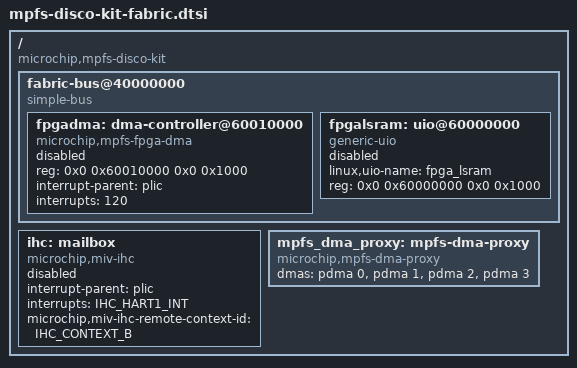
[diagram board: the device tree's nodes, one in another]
// SPDX-License-Identifier: (GPL-2.0 OR MIT)
/* Copyright (c) 2020-2021 Microchip Technology Inc */

#include "dt-bindings/mailbox/miv-ihc.h"

/ {
	compatible = "microchip,mpfs-disco-kit", "microchip,mpfs";

	fabric-bus@40000000 {
		compatible = "simple-bus";
		#address-cells = <2>;
		#size-cells = <2>;
		ranges = <0x0 0x40000000 0x0 0x40000000 0x0 0x20000000>, /* FIC3-FAB */
			 <0x0 0x60000000 0x0 0x60000000 0x0 0x20000000>, /* FIC0, LO */
			 <0x0 0xe0000000 0x0 0xe0000000 0x0 0x20000000>, /* FIC1, LO */
			 <0x20 0x0 0x20 0x0 0x10 0x0>, /* FIC0,HI */
			 <0x30 0x0 0x30 0x0 0x10 0x0>; /* FIC1,HI */

		fpgadma: dma-controller@60010000 {
			compatible = "microchip,mpfs-fpga-dma";
			reg = <0x0 0x60010000 0x0 0x1000>;
			interrupt-parent = <&plic>;
			interrupts = <120>;
			#dma-cells = <1>;
			status = "disabled";
		};

		fpgalsram: uio@60000000 {
			compatible = "generic-uio";
			linux,uio-name = "fpga_lsram";
			reg = <0x0 0x60000000 0x0 0x1000>;
			status = "disabled";
		};
	};

	ihc: mailbox {
		compatible = "microchip,miv-ihc";
		interrupt-parent = <&plic>;
		interrupts = <IHC_HART1_INT>;
		microchip,miv-ihc-remote-context-id = <IHC_CONTEXT_B>;
		#mbox-cells = <1>;
		status = "disabled";
	};

	mpfs_dma_proxy: mpfs-dma-proxy {
		compatible = "microchip,mpfs-dma-proxy";
		dmas = <&pdma 0>, <&pdma 1>, <&pdma 2>, <&pdma 3>;
		dma-names = "dma-proxy0", "dma-proxy1", "dma-proxy2", "dma-proxy3";
	};
};
